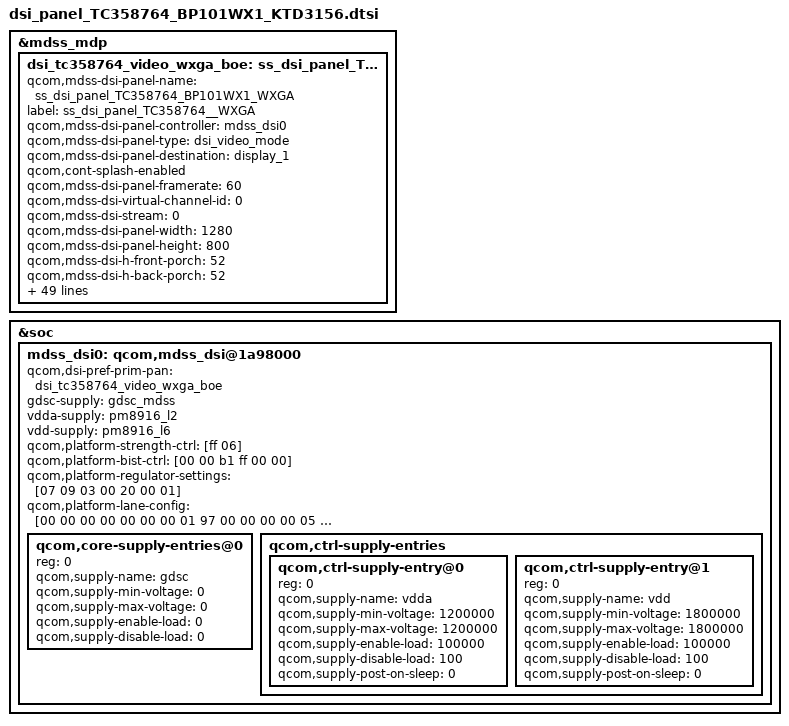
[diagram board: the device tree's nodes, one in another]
/* Copyright (c) 2013, The Linux Foundation. All rights reserved.
 *
 * This program is free software; you can redistribute it and/or modify
 * it under the terms of the GNU General Public License version 2 and
 * only version 2 as published by the Free Software Foundation.
 *
 * This program is distributed in the hope that it will be useful,
 * but WITHOUT ANY WARRANTY; without even the implied warranty of
 * MERCHANTABILITY or FITNESS FOR A PARTICULAR PURPOSE.  See the
 * GNU General Public License for more details.
 */

/*---------------------------------------------------------------------------
 * This file is autogenerated file using gcdb parser. Please do not edit it.
 * Update input XML file to add a new entry or update variable in this file
 * VERSION = "1.0"
 *---------------------------------------------------------------------------*/
&mdss_mdp {
	dsi_tc358764_video_wxga_boe: ss_dsi_panel_TC358764_BP101WX1_WXGA {
		qcom,mdss-dsi-panel-name = "ss_dsi_panel_TC358764_BP101WX1_WXGA";/*BOE panel*/
		label = "ss_dsi_panel_TC358764__WXGA";
		qcom,mdss-dsi-panel-controller = <&mdss_dsi0>;
		qcom,mdss-dsi-panel-type = "dsi_video_mode";
		qcom,mdss-dsi-panel-destination = "display_1";
		qcom,cont-splash-enabled;
		qcom,mdss-dsi-panel-framerate = <60>;
		qcom,mdss-dsi-virtual-channel-id = <0>;
		qcom,mdss-dsi-stream = <0>;
		qcom,mdss-dsi-panel-width = <1280>;
		qcom,mdss-dsi-panel-height = <800>;

		qcom,mdss-dsi-h-front-porch = <52>;
		qcom,mdss-dsi-h-back-porch = <52>;
		qcom,mdss-dsi-h-pulse-width = <4>;

		qcom,mdss-dsi-h-sync-skew = <0>;

		qcom,mdss-dsi-v-back-porch = <66>;
		qcom,mdss-dsi-v-front-porch = <68>;
		qcom,mdss-dsi-v-pulse-width = <6>;

		qcom,mdss-dsi-h-left-border = <0>;
		qcom,mdss-dsi-h-right-border = <0>;
		qcom,mdss-dsi-v-top-border = <0>;
		qcom,mdss-dsi-v-bottom-border = <0>;
		qcom,mdss-dsi-bpp = <24>;
		qcom,mdss-dsi-underflow-color = <0xff>;
		qcom,mdss-dsi-border-color = <0>;
		qcom,mdss-dsi-on-command = [
/*TC358764/65XBG DSI Basic Parameters*/
			29 01 00 00 00 00 06 3C 01 06 00 05 00
			29 01 00 00 00 00 06 14 01 04 00 00 00
			29 01 00 00 00 00 06 64 01 04 00 00 00 /*3*/
			29 01 00 00 00 00 06 68 01 04 00 00 00
			29 01 00 00 00 00 06 6C 01 04 00 00 00
			29 01 00 00 00 00 06 70 01 04 00 00 00 /*6*/
			29 01 00 00 00 00 06 34 01 1F 00 00 00
			29 01 00 00 00 00 06 10 02 1F 00 00 00
			29 01 00 00 00 00 06 04 01 01 00 00 00 /*9*/
			29 01 00 00 00 00 06 04 02 01 00 00 00

/*TC358764/65XBG Timing and mode setting*/
			29 01 00 00 00 00 06 50 04 20 01 F0 03
			29 01 00 00 00 00 06 54 04 02 00 30 00 /*12*/
			29 01 00 00 00 00 06 58 04 20 03 30 00
			29 01 00 00 00 00 06 5C 04 02 00 40 00
			29 01 00 00 00 00 06 60 04 00 05 20 00 /*15*/

			29 01 00 00 00 00 06 64 04 01 00 00 00
			29 01 00 00 02 00 06 A0 04 06 80 44 00
			29 01 00 00 02 00 06 A0 04 06 80 04 00 /*18*/
			29 01 00 00 02 00 06 04 05 04 00 00 00
/*TC358764/65XBG LVDS Color mapping setting	*/

			29 01 00 00 00 00 06 80 04 00 01 02 03
			29 01 00 00 00 00 06 84 04 04 07 05 08
			29 01 00 00 00 00 06 88 04 09 0A 0E 0F
			29 01 00 00 00 00 06 8C 04 0B 0C 0D 10
			29 01 00 00 00 00 06 90 04 16 17 11 12
			29 01 00 00 00 00 06 94 04 13 14 15 1B
			29 01 00 00 00 00 06 98 04 18 19 1A 06
/*TC358764/65XBG LVDS enable*/
			29 01 00 00 00 00 06 9C 04 01 00 00 00
			];
		qcom,mdss-dsi-on-command-state = "dsi_lp_mode";
		qcom,mdss-dsi-off-command-state = "dsi_hs_mode";
		qcom,mdss-dsi-off-command = [29 01 00 00 01 00 06 A0 04 01 00 00 00
			29 01 00 00 00 00 06 9C 04 00 00 00 00
		];

		samsung,support_panel_max = <1>;

		qcom,mdss-dsi-h-sync-pulse = <0>;
		qcom,mdss-dsi-bllp-eof-power-mode;
		qcom,mdss-dsi-bllp-power-mode;
		qcom,mdss-dsi-lane-0-state;
		qcom,mdss-dsi-lane-1-state;
		qcom,mdss-dsi-lane-2-state;
		qcom,mdss-dsi-lane-3-state;
		qcom,mdss-dsi-panel-timings = [88 1e 12 00 42 46 18 20 16 03 04 00]; /*470Mhz*/

		qcom,mdss-dsi-t-clk-pre = <0x1b>;
		qcom,mdss-dsi-t-clk-post = <0x04>;
		qcom,mdss-dsi-bl-min-level = <1>;
		qcom,mdss-dsi-bl-max-level = <255>;
		qcom,mdss-dsi-dma-trigger = "trigger_sw";
		qcom,mdss-dsi-mdp-trigger = "none";
		qcom,mdss-dsi-bl-pmic-control-type = "bl_ctrl_ss_pwm";
		samsung,tft-common-support;
		samsung,backlight-gpio-config;
		samsung,backlight-pwm-ap-support;
		qcom,mdss-dsi-reset-sequence = <1 1>, <0 1>, <1 1>;
		qcom,mdss-pan-physical-width-dimension = <228>;
		qcom,mdss-pan-physical-height-dimension = <149>;
		qcom,mdss-dsi-lp11-init;
		qcom,mdss-dsi-init-delay-us = <100>;
		qcom,mdss-dsi-additional-delay = <500>; /* for panel spec (T7)*/
		/*samsung,dsi-lp11-init;  */
		qcom,mdss-dsi-force-clk-lane-hs = <1>;
		qcom,mdss-dsi-traffic-mode = "non_burst_sync_pulse";
		qcom,mdss-dsi-lane-map = <0>;

/*		samsung,tft_pwm_tx_cmds_revA=[
			39 01 00 00 00 00 02 51 FF
		];*/
	};
};
&soc {
	mdss_dsi0: qcom,mdss_dsi@1a98000 {
		qcom,dsi-pref-prim-pan = <&dsi_tc358764_video_wxga_boe>;

		gdsc-supply = <&gdsc_mdss>;
		vdda-supply = <&pm8916_l2>;
		vdd-supply = <&pm8916_l6>;
		qcom,platform-strength-ctrl = [ff 06];
		qcom,platform-bist-ctrl = [00 00 b1 ff 00 00];
		qcom,platform-regulator-settings = [07 09 03 00 20 00 01];
		qcom,platform-lane-config = [00 00 00 00 00 00 00 01 97
			00 00 00 00 05 00 00 01 97
			00 00 00 00 0a 00 00 01 97
			00 00 00 00 0f 00 00 01 97
			00 c0 00 00 00 00 00 01 bb];

		qcom,core-supply-entries@0 {
				reg = <0>;
				qcom,supply-name = "gdsc";
				qcom,supply-min-voltage = <0>;
				qcom,supply-max-voltage = <0>;
				qcom,supply-enable-load = <0>;
				qcom,supply-disable-load = <0>;
			};


		qcom,ctrl-supply-entries {
			#address-cells = <1>;
			#size-cells = <0>;

			qcom,ctrl-supply-entry@0 {
				reg = <0>;
				qcom,supply-name = "vdda";
				qcom,supply-min-voltage = <1200000>;
				qcom,supply-max-voltage = <1200000>;
				qcom,supply-enable-load = <100000>;
				qcom,supply-disable-load = <100>;
				qcom,supply-post-on-sleep = <0>;
			};
		};
		qcom,ctrl-supply-entries {
			#address-cells = <1>;
			#size-cells = <0>;

			qcom,ctrl-supply-entry@1 {
				reg = <0>;
				qcom,supply-name = "vdd";
				qcom,supply-min-voltage = <1800000>;
				qcom,supply-max-voltage = <1800000>;
				qcom,supply-enable-load = <100000>;
				qcom,supply-disable-load = <100>;
				qcom,supply-post-on-sleep = <0>;
			};
		};
	};

};
